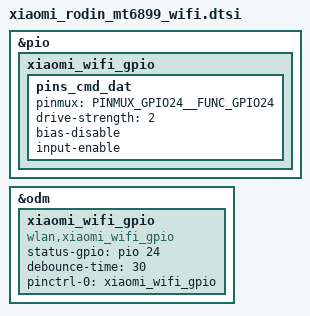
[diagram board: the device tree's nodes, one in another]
// SPDX-License-Identifier: (GPL-2.0 OR MIT)
/*
 * Copyright (C) 2023 MediaTek Inc.
 */

&pio {
	xiaomi_wifi_gpio: xiaomi_wifi_gpio {
                pins_cmd_dat {
			pinmux = <PINMUX_GPIO24__FUNC_GPIO24>;
			drive-strength = <2>;
			bias-disable;
			input-enable;
		};
	};

};

&odm {
	xiaomi_wifi_gpio {
		compatible = "wlan,xiaomi_wifi_gpio";
		status-gpio = <&pio 24 0>;
		debounce-time = <30>;
		pinctrl-names = "default";
		pinctrl-0 = <&xiaomi_wifi_gpio>;
	};
};
